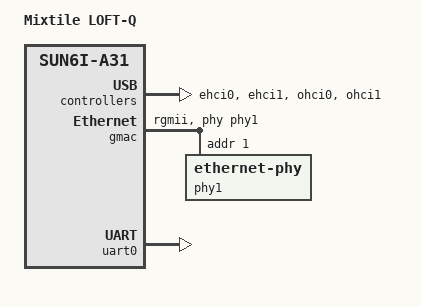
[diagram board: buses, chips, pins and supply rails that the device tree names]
// SPDX-License-Identifier: GPL-2.0+ OR X11
/*
 * Copyright 2015 Hans de Goede <hdegoede@redhat.com>
 *
 * Minimal dts file for the Mixtile LOFT-Q for u-boot only
 */

/dts-v1/;
#include "sun6i-a31.dtsi"

/ {
	model = "Mixtile LOFT-Q";
	compatible = "mixtile,loft-q", "allwinner,sun6i-a31";

	aliases {
		serial0 = &uart0;
	};

	chosen {
		stdout-path = "serial0:115200n8";
	};
};

&ehci0 {
	status = "okay";
};

&ehci1 {
	status = "okay";
};

&gmac {
	pinctrl-names = "default";
	pinctrl-0 = <&gmac_pins_rgmii_a>;
	phy = <&phy1>;
	phy-mode = "rgmii";
	status = "okay";

	phy1: ethernet-phy@1 {
		reg = <1>;
	};
};

&ohci0 {
	status = "okay";
};

&ohci1 {
	status = "okay";
};

&uart0 {
	pinctrl-names = "default";
	pinctrl-0 = <&uart0_pins_a>;
	status = "okay";
};
